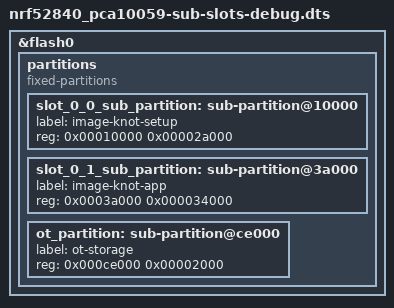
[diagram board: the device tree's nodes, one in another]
/*
 * Overlay file to permit using sub-slots with extend space for setup app.
 * This file is meant for apps on debug mode, not stock mode.
 */
&flash0 {
	/*
	 * For more information, see:
	 * http://docs.zephyrproject.org/latest/devices/dts/flash_partitions.html
	 */
	partitions {
		compatible = "fixed-partitions";
		#address-cells = <1>;
		#size-cells = <1>;

		/*
		 * Hack: Split image-0 into two sub-images
		 * (knot-setup and knot-app) so they can be refer to each other
		 * and recognized by MCUBOOT as a single image.
		 */

		slot_0_0_sub_partition: sub-partition@10000 {
			label = "image-knot-setup";
			reg = <0x00010000 0x00002a000>;
		};

		slot_0_1_sub_partition: sub-partition@3a000 {
			label = "image-knot-app";
			reg = <0x0003a000 0x000034000>;
		};

		/*
		 * Using first 4 pages of scratch partition for
		 * OpenThread storage.
		 * This is allowed as the scratch area is used only
		 * during OTA update.
		 */
		ot_partition: sub-partition@ce000 {
			label = "ot-storage";
			reg = <0x000ce000 0x00002000>;
		};
	};
};
